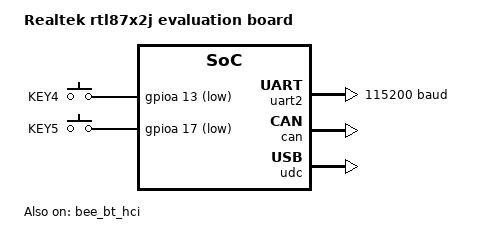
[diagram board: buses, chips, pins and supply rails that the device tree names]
/*
 * Copyright (c) 2026, Realtek Semiconductor Corporation.
 * SPDX-License-Identifier: Apache-2.0
 */
/dts-v1/;
#include <realtek/bee/rtl87x2j.dtsi>
#include <dt-bindings/pinctrl/rtl87x2j-pinctrl.h>
#include "rtl87x2j_evb_rtl8762jth-pinctrl.dtsi"
#include <zephyr/dt-bindings/input/input-event-codes.h>

/ {
	model = "Realtek rtl87x2j evaluation board";
	compatible = "realtek,rtl87x2j_evb";

	chosen {
		zephyr,sram = &sram;
		zephyr,flash = &eflash;
		zephyr,code-partition = &app_partition;
		zephyr,console = &uart2;
		zephyr,shell-uart = &uart2;
		zephyr,bt-hci = &bee_bt_hci;
		zephyr,canbus = &can;
	};

	gpio_keys {
		compatible = "gpio-keys";

		key4: key4 {
			gpios = <&gpioa 13 (GPIO_PULL_UP | GPIO_ACTIVE_LOW)>;
			label = "KEY4";
			zephyr,code = <INPUT_KEY_0>;
		};

		key5: key5 {
			gpios = <&gpioa 17 (GPIO_PULL_UP | GPIO_ACTIVE_LOW)>;
			label = "KEY5";
			zephyr,code = <INPUT_KEY_1>;
		};
	};
};

&eflash {
	partitions {
		/* 0x2019000-0x3000000: Free space for Zephyr
		 * bt_controller is Realtek's internal Bluetooth controller firmware image.
		 * Different versions may be used based on features (default: 217K).
		 * Flash layout may need adjustment when bt_controller size changes.
		 */
		bt_controller: partition@19000 {
			label = "bt-controller";
			reg = <0x19000 DT_SIZE_K(217)>;
		};

		app_partition: partition@4f400 {
			label = "application";
			reg = <0x4f400 DT_SIZE_K(403)>;
		};
	};
};

&eflash_nvr {
	partitions {
		/* 0x2201000-0x2208800: Free space for Zephyr */
		storage_partition: partition@1000 {
			label = "storage";
			reg = <0x1000 DT_SIZE_K(30)>;
		};
	};
};

&cpu {
	clock-frequency = <40000000>;
};

&gpioa {
	pinctrl-0 = <&gpioa_default>;
	pinctrl-names = "default";
	status = "okay";
};

&uart2 {
	pinctrl-0 = <&uart2_default>;
	pinctrl-1 = <&uart2_sleep>;
	pinctrl-names = "default", "sleep";
	status = "okay";
	current-speed = <115200>;
	parity = "none";
	stop-bits = "1";
	data-bits = <8>;
};

&can {
	pinctrl-0 = <&can_default>;
	pinctrl-names = "default";
	status = "okay";
};

&bee_bt_hci {
	status = "okay";
};

zephyr_udc0: &udc {
	status = "okay";
};
